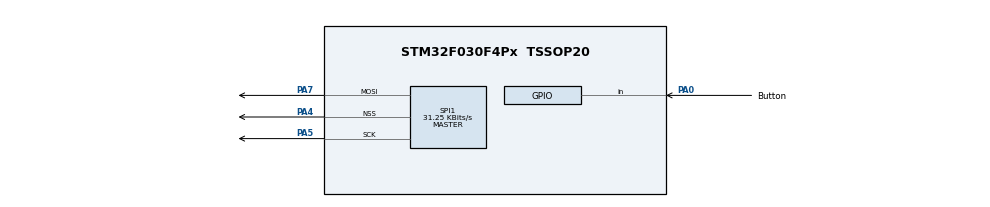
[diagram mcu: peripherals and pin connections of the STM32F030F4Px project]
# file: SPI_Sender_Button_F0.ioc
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Mcu.Family=STM32F0
Mcu.Name=STM32F030F4Px
Mcu.Package=TSSOP20
PA0.GPIO_Label=Button
PA0.Signal=GPIO_Input
PA13.Mode=Serial_Wire
PA13.Signal=SYS_SWDIO
PA14.Mode=Serial_Wire
PA14.Signal=SYS_SWCLK
PA4.Mode=NSS_Signal_Hard_Output
PA4.Signal=SPI1_NSS
PA5.Mode=TX_Only_Simplex_Unidirect_Master
PA5.Signal=SPI1_SCK
PA7.Mode=TX_Only_Simplex_Unidirect_Master
PA7.Signal=SPI1_MOSI
ProjectManager.HeapSize=0x200
ProjectManager.StackSize=0x400
ProjectManager.TargetToolchain=STM32CubeIDE
SPI1.BaudRatePrescaler=SPI_BAUDRATEPRESCALER_256
SPI1.CalculateBaudRate=31.25 KBits/s
SPI1.DataSize=SPI_DATASIZE_8BIT
SPI1.Direction=SPI_DIRECTION_2LINES
SPI1.Mode=SPI_MODE_MASTER
SPI1.VirtualNSS=VM_NSSHARD
SPI1.VirtualType=VM_MASTER
board=custom

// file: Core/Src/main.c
/* USER CODE BEGIN Header */
/**
  ******************************************************************************
  * @file           : main.c
  * @brief          : Main program body
  ******************************************************************************
  * @attention
  *
  * <h2><center>&copy; Copyright (c) 2021 STMicroelectronics.
  * All rights reserved.</center></h2>
  *
  * This software component is licensed by ST under BSD 3-Clause license,
  * the "License"; You may not use this file except in compliance with the
  * License. You may obtain a copy of the License at:
  *                        opensource.org/licenses/BSD-3-Clause
  *
  ******************************************************************************
  */
/* USER CODE END Header */
#include "main.h"

SPI_HandleTypeDef hspi1;

void SystemClock_Config(void);
static void MX_GPIO_Init(void);
static void MX_SPI1_Init(void);

int main(void)
{

  /* MCU Configuration--------------------------------------------------------*/

  /* Reset of all peripherals, Initializes the Flash interface and the Systick. */
  HAL_Init();

  /* Configure the system clock */
  SystemClock_Config();

  /* Initialize all configured peripherals */
  MX_GPIO_Init();
  MX_SPI1_Init();

  /* Infinite loop */
  /* USER CODE BEGIN WHILE */
  uint8_t i = 1;
  while (1)
  {
	  if (HAL_GPIO_ReadPin(Button_GPIO_Port, Button_Pin) == GPIO_PIN_RESET)
	  {
		  HAL_SPI_Transmit(&hspi1, &i, sizeof(i), 10);
		  i++;
		  HAL_Delay(500);
	  }

    /* USER CODE END WHILE */

  }
}

void SystemClock_Config(void)
{
  RCC_OscInitTypeDef RCC_OscInitStruct = {0};
  RCC_ClkInitTypeDef RCC_ClkInitStruct = {0};

  /** Initializes the RCC Oscillators according to the specified parameters
  * in the RCC_OscInitTypeDef structure.
  */
  RCC_OscInitStruct.OscillatorType = RCC_OSCILLATORTYPE_HSI;
  RCC_OscInitStruct.HSIState = RCC_HSI_ON;
  RCC_OscInitStruct.HSICalibrationValue = RCC_HSICALIBRATION_DEFAULT;
  RCC_OscInitStruct.PLL.PLLState = RCC_PLL_NONE;
  if (HAL_RCC_OscConfig(&RCC_OscInitStruct) != HAL_OK)
  {
    Error_Handler();
  }
  /** Initializes the CPU, AHB and APB buses clocks
  */
  RCC_ClkInitStruct.ClockType = RCC_CLOCKTYPE_HCLK|RCC_CLOCKTYPE_SYSCLK
                              |RCC_CLOCKTYPE_PCLK1;
  RCC_ClkInitStruct.SYSCLKSource = RCC_SYSCLKSOURCE_HSI;
  RCC_ClkInitStruct.AHBCLKDivider = RCC_SYSCLK_DIV1;
  RCC_ClkInitStruct.APB1CLKDivider = RCC_HCLK_DIV1;

  if (HAL_RCC_ClockConfig(&RCC_ClkInitStruct, FLASH_LATENCY_0) != HAL_OK)
  {
    Error_Handler();
  }
}

static void MX_SPI1_Init(void)
{

  /* SPI1 parameter configuration*/
  hspi1.Instance = SPI1;
  hspi1.Init.Mode = SPI_MODE_MASTER;
  hspi1.Init.Direction = SPI_DIRECTION_2LINES;
  hspi1.Init.DataSize = SPI_DATASIZE_8BIT;
  hspi1.Init.CLKPolarity = SPI_POLARITY_LOW;
  hspi1.Init.CLKPhase = SPI_PHASE_1EDGE;
  hspi1.Init.NSS = SPI_NSS_HARD_OUTPUT;
  hspi1.Init.BaudRatePrescaler = SPI_BAUDRATEPRESCALER_256;
  hspi1.Init.FirstBit = SPI_FIRSTBIT_MSB;
  hspi1.Init.TIMode = SPI_TIMODE_DISABLE;
  hspi1.Init.CRCCalculation = SPI_CRCCALCULATION_DISABLE;
  hspi1.Init.CRCPolynomial = 7;
  hspi1.Init.CRCLength = SPI_CRC_LENGTH_DATASIZE;
  hspi1.Init.NSSPMode = SPI_NSS_PULSE_ENABLE;
  if (HAL_SPI_Init(&hspi1) != HAL_OK)
  {
    Error_Handler();
  }

}

static void MX_GPIO_Init(void)
{
  GPIO_InitTypeDef GPIO_InitStruct = {0};

  /* GPIO Ports Clock Enable */
  __HAL_RCC_GPIOA_CLK_ENABLE();

  /*Configure GPIO pin : Button_Pin */
  GPIO_InitStruct.Pin = Button_Pin;
  GPIO_InitStruct.Mode = GPIO_MODE_INPUT;
  GPIO_InitStruct.Pull = GPIO_NOPULL;
  HAL_GPIO_Init(Button_GPIO_Port, &GPIO_InitStruct);

}

void Error_Handler(void)
{
  __disable_irq();
  while (1)
  {
  }
}

/************************ (C) COPYRIGHT STMicroelectronics *****END OF FILE****/
